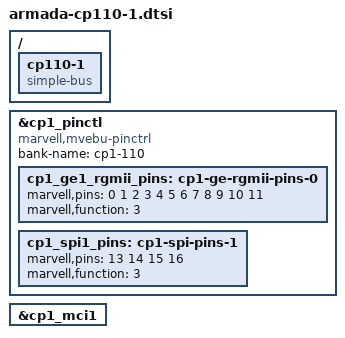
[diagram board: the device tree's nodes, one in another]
/*
 * Copyright (C) 2016 Marvell Technology Group Ltd.
 *
 * This file is dual-licensed: you can use it either under the terms
 * of the GPLv2 or the X11 license, at your option. Note that this dual
 * licensing only applies to this file, and not this project as a
 * whole.
 *
 *  a) This library is free software; you can redistribute it and/or
 *     modify it under the terms of the GNU General Public License as
 *     published by the Free Software Foundation; either version 2 of the
 *     License, or (at your option) any later version.
 *
 *     This library is distributed in the hope that it will be useful,
 *     but WITHOUT ANY WARRANTY; without even the implied warranty of
 *     MERCHANTABILITY or FITNESS FOR A PARTICULAR PURPOSE.  See the
 *     GNU General Public License for more details.
 *
 * Or, alternatively,
 *
 *  b) Permission is hereby granted, free of charge, to any person
 *     obtaining a copy of this software and associated documentation
 *     files (the "Software"), to deal in the Software without
 *     restriction, including without limitation the rights to use,
 *     copy, modify, merge, publish, distribute, sublicense, and/or
 *     sell copies of the Software, and to permit persons to whom the
 *     Software is furnished to do so, subject to the following
 *     conditions:
 *
 *     The above copyright notice and this permission notice shall be
 *     included in all copies or substantial portions of the Software.
 *
 *     THE SOFTWARE IS PROVIDED "AS IS", WITHOUT WARRANTY OF ANY KIND,
 *     EXPRESS OR IMPLIED, INCLUDING BUT NOT LIMITED TO THE WARRANTIES
 *     OF MERCHANTABILITY, FITNESS FOR A PARTICULAR PURPOSE AND
 *     NONINFRINGEMENT. IN NO EVENT SHALL THE AUTHORS OR COPYRIGHT
 *     HOLDERS BE LIABLE FOR ANY CLAIM, DAMAGES OR OTHER LIABILITY,
 *     WHETHER IN AN ACTION OF CONTRACT, TORT OR OTHERWISE, ARISING
 *     FROM, OUT OF OR IN CONNECTION WITH THE SOFTWARE OR THE USE OR
 *     OTHER DEALINGS IN THE SOFTWARE.
 */

/*
 * Device Tree file for Marvell Armada CP110-1.
 */

#include "armada-common.dtsi"

#define CP110_NAME		cp1
#define CP110_BASE		0xf4000000
#define CP110_PCIE_IO_BASE	0xfd000000
#define CP110_PCIE_MEM_BASE	0xfa000000

/ {
	cp110-1 {
		#address-cells = <2>;
		#size-cells = <2>;
		compatible = "simple-bus";
		ranges;

		#include "armada-cp110.dtsi"
	};
};

#undef CP110_NAME
#undef CP110_BASE
#undef CP110_PCIE_IO_BASE
#undef CP110_PCIE_MEM_BASE

&cp1_pinctl {
	compatible = "marvell,mvebu-pinctrl", "marvell,a80x0-cp1-pinctrl";
	bank-name ="cp1-110";

	cp1_ge1_rgmii_pins: cp1-ge-rgmii-pins-0 {
		marvell,pins = < 0 1 2 3 4 5 6 7 8 9 10 11 >;
		marvell,function = <3>;
	};
	cp1_spi1_pins: cp1-spi-pins-1 {
		marvell,pins = < 13 14 15 16 >;
		marvell,function = <3>;
	};
};

&cp1_mci1 {
	status = "okay";
};
